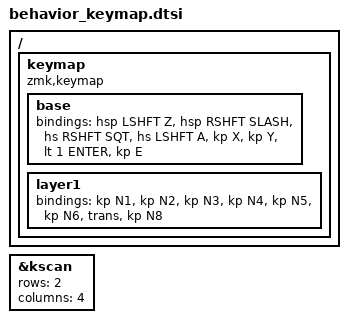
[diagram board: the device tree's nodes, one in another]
// Simulator tests for hold-follow-key-positions in src/behaviors/behavior_hold_tap_follow.c; run ./test.sh
#include <dt-bindings/zmk/keys.h>
#include <behaviors.dtsi>
#include <dt-bindings/zmk/kscan_mock.h>

// Mirrors the Z, /, ' and A keys in config/corne.keymap.
// Positions: 0 = Z/Shift (hsp), 1 = //Shift (hsp), 2 = '/Shift (hs), 3 = A/Shift (hs),
//            4 = X, 5 = Y, 6 = Enter/layer 1 (lt), 7 = E
&kscan { rows = <2>; columns = <4>; };

// The real hold-taps from config/common/behaviors.dtsi, with this test layout's positions.
#define HS_FOLLOW_POS 3     // A
#define HSP_FOLLOW_POS 1    // /
#include "../../config/common/behaviors.dtsi"

/ {
    keymap {
        compatible = "zmk,keymap";
        base   { bindings = <&hsp LSHFT Z &hsp RSHFT SLASH &hs RSHFT SQT &hs LSHFT A &kp X &kp Y &lt 1 ENTER &kp E>; };
        layer1 { bindings = <&kp N1 &kp N2 &kp N3 &kp N4 &kp N5 &kp N6 &trans &kp N8>; };
    };
};
